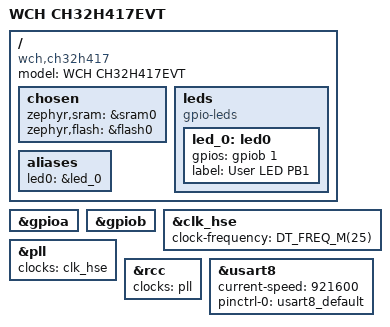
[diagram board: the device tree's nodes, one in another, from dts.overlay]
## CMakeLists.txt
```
cmake_minimum_required(VERSION 3.20.0)
find_package(Zephyr REQUIRED HINTS $ENV{ZEPHYR_BASE})

project(v5f)

rust_cargo_application()
```

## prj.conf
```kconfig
# V5F application configuration

CONFIG_GPIO=y
CONFIG_SERIAL=y

# No console on USART8: the Rust application owns the UART and speaks the
# SUMP (logic analyzer) protocol on it. Any kernel log output would corrupt
# the binary stream.
# CONFIG_CONSOLE is not set
# CONFIG_UART_CONSOLE is not set

# Rust application support (zephyr-lang-rust module).
CONFIG_RUST=y
CONFIG_RUST_ALLOC=y

# The Rust main runs on the main thread; give it room for logging.
CONFIG_MAIN_STACK_SIZE=8192
```

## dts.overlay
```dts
#include <wch/ch32h417/ch32h417_v5f.dtsi>
#include "../ch32h417evt-pinctrl.dtsi"
#include <zephyr/dt-bindings/gpio/gpio.h>

/ {
	model = "WCH CH32H417EVT";
	compatible = "wch,ch32h417";

	chosen {
		zephyr,sram = &sram0;
		zephyr,flash = &flash0;
		/* No console: USART8 is owned by the SUMP logic-analyzer
		 * protocol running in the Rust application. */
	};

	leds {
		compatible = "gpio-leds";
		status = "okay";

		led_0: led0 {
			gpios = <&gpiob 1 GPIO_ACTIVE_HIGH>;
			label = "User LED PB1";
		};
	};

	aliases {
		led0 = &led_0;
	};
};

&gpioa {
	status = "okay";
};

&gpiob {
	status = "okay";
};

&clk_hse {
	clock-frequency = <DT_FREQ_M(25)>;
	status = "okay";
};

&pll {
	clocks = <&clk_hse>;
	status = "okay";
};

&rcc {
	clocks = <&pll>;
};

&usart8 {
	status = "okay";
	current-speed = <921600>;
	pinctrl-0 = <&usart8_default>;
	pinctrl-names = "default";
};
```

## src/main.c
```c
/*
 * CH32H417EVT V5F application: blink the on-board LED and print on USART8.
 */

#include <zephyr/kernel.h>
#include <zephyr/drivers/gpio.h>

#define LED0_NODE DT_ALIAS(led0)

static const struct gpio_dt_spec led = GPIO_DT_SPEC_GET(LED0_NODE, gpios);

int main(void)
{
	gpio_pin_configure_dt(&led, GPIO_OUTPUT_ACTIVE);
	printk("Hello from CH32H417EVT V5F!\n");

	while (1) {
		gpio_pin_toggle_dt(&led);
		printk("LED toggle\n");
		k_sleep(K_MSEC(500));
	}
}
```
